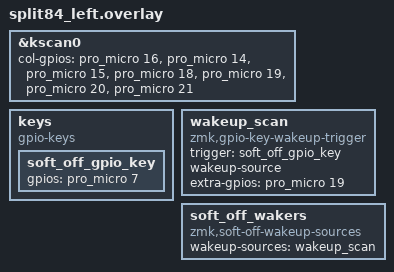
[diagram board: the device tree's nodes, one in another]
#include "split84.dtsi"

&kscan0 {
	col-gpios
		= <&pro_micro 16 GPIO_ACTIVE_HIGH>
		, <&pro_micro 14 GPIO_ACTIVE_HIGH>
		, <&pro_micro 15 GPIO_ACTIVE_HIGH>
		, <&pro_micro 18 GPIO_ACTIVE_HIGH>
		, <&pro_micro 19 GPIO_ACTIVE_HIGH>
		, <&pro_micro 20 GPIO_ACTIVE_HIGH>
		, <&pro_micro 21 GPIO_ACTIVE_HIGH>
		;
};

/* --- Wakeup after Soft-off using space key --- */
keys {
	compatible = "gpio-keys";
	soft_off_gpio_key: soft_off_gpio_key {
		gpios = <&pro_micro 7  (GPIO_ACTIVE_HIGH | GPIO_PULL_DOWN)>; // last row
	};
};

wakeup_scan: wakeup_scan {
	compatible = "zmk,gpio-key-wakeup-trigger";
	trigger = <&soft_off_gpio_key>;
	wakeup-source;
	extra-gpios = <&pro_micro 19 GPIO_ACTIVE_HIGH>; // col 6
};

soft_off_wakers {
	compatible = "zmk,soft-off-wakeup-sources";
	wakeup-sources = <&wakeup_scan>;
};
